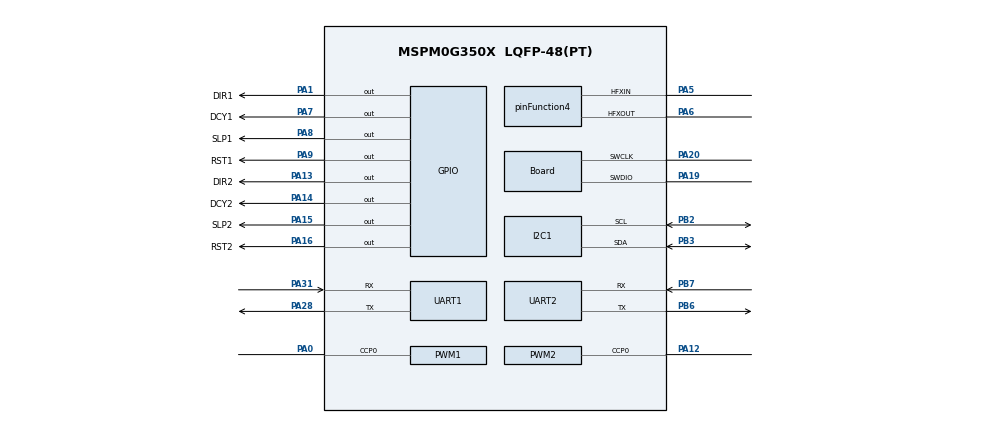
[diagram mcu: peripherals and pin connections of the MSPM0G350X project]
/**
 * @cliArgs --device "MSPM0G350X" --part "Default" --package "LQFP-48(PT)" --product "mspm0_sdk@2.05.01.00"
 * @versions {"tool":"1.24.1+4189"}
 */

/**
 * Import the modules used in this configuration.
 */
const GPIO   = scripting.addModule("/ti/driverlib/GPIO", {}, false);
const GPIO1  = GPIO.addInstance();
const GPIO2  = GPIO.addInstance();
const I2C    = scripting.addModule("/ti/driverlib/I2C", {}, false);
const I2C1   = I2C.addInstance();
const PWM    = scripting.addModule("/ti/driverlib/PWM", {}, false);
const PWM1   = PWM.addInstance();
const PWM2   = PWM.addInstance();
const SYSCTL = scripting.addModule("/ti/driverlib/SYSCTL");
const UART   = scripting.addModule("/ti/driverlib/UART", {}, false);
const UART1  = UART.addInstance();
const UART2  = UART.addInstance();

/**
 * Write custom configuration values to the imported modules.
 */
const divider9       = system.clockTree["UDIV"];
divider9.divideValue = 2;

const multiplier2         = system.clockTree["PLL_QDIV"];
multiplier2.multiplyValue = 5;

const mux4       = system.clockTree["EXHFMUX"];
mux4.inputSelect = "EXHFMUX_XTAL";

const mux8       = system.clockTree["HSCLKMUX"];
mux8.inputSelect = "HSCLKMUX_SYSPLL0";

const pinFunction4                        = system.clockTree["HFXT"];
pinFunction4.inputFreq                    = 40;
pinFunction4.enable                       = true;
pinFunction4.peripheral.$assign           = "SYSCTL";
pinFunction4.peripheral.hfxInPin.$assign  = "PA5";
pinFunction4.peripheral.hfxOutPin.$assign = "PA6";

GPIO1.$name                         = "STEP_MOTOR1";
GPIO1.port                          = "PORTA";
GPIO1.associatedPins.create(4);
GPIO1.associatedPins[0].$name       = "DIR1";
GPIO1.associatedPins[0].pin.$assign = "PA1";
GPIO1.associatedPins[1].$name       = "DCY1";
GPIO1.associatedPins[1].pin.$assign = "PA7";
GPIO1.associatedPins[2].$name       = "SLP1";
GPIO1.associatedPins[2].pin.$assign = "PA8";
GPIO1.associatedPins[3].$name       = "RST1";
GPIO1.associatedPins[3].pin.$assign = "PA9";

const Board                       = scripting.addModule("/ti/driverlib/Board", {}, false);
Board.peripheral.$assign          = "DEBUGSS";
Board.peripheral.swclkPin.$assign = "PA20";
Board.peripheral.swdioPin.$assign = "PA19";

GPIO2.$name                         = "STEP_MOTOR2";
GPIO2.port                          = "PORTA";
GPIO2.associatedPins.create(4);
GPIO2.associatedPins[0].$name       = "DIR2";
GPIO2.associatedPins[0].pin.$assign = "PA13";
GPIO2.associatedPins[1].$name       = "DCY2";
GPIO2.associatedPins[1].pin.$assign = "PA14";
GPIO2.associatedPins[2].$name       = "SLP2";
GPIO2.associatedPins[2].pin.$assign = "PA15";
GPIO2.associatedPins[3].$name       = "RST2";
GPIO2.associatedPins[3].pin.$assign = "PA16";

I2C1.$name                             = "OLED";
I2C1.basicEnableController             = true;
I2C1.advDigitalGlitchFilter            = "CLOCKS_1";
I2C1.advControllerRXFIFOTRIG           = "BYTES_8";
I2C1.advControllerTXFIFOTRIG           = "BYTES_7";
I2C1.enableDMAEvent1                   = false;
I2C1.enableDMAEvent2                   = false;
I2C1.peripheral.$assign                = "I2C1";
I2C1.peripheral.sdaPin.$assign         = "PB3";
I2C1.peripheral.sclPin.$assign         = "PB2";
I2C1.sdaPinConfig.$name                = "ti_driverlib_gpio_GPIOPinGeneric0";
I2C1.sdaPinConfig.hideOutputInversion  = scripting.forceWrite(false);
I2C1.sdaPinConfig.onlyInternalResistor = scripting.forceWrite(false);
I2C1.sdaPinConfig.passedPeripheralType = scripting.forceWrite("Digital");
I2C1.sdaPinConfig.enableConfig         = true;
I2C1.sdaPinConfig.internalResistor     = "PULL_UP";
I2C1.sclPinConfig.$name                = "ti_driverlib_gpio_GPIOPinGeneric1";
I2C1.sclPinConfig.hideOutputInversion  = scripting.forceWrite(false);
I2C1.sclPinConfig.onlyInternalResistor = scripting.forceWrite(false);
I2C1.sclPinConfig.passedPeripheralType = scripting.forceWrite("Digital");
I2C1.sclPinConfig.enableConfig         = true;
I2C1.sclPinConfig.internalResistor     = "PULL_UP";

PWM1.$name                              = "DCC_100_PWM1";
PWM1.ccIndex                            = [0];
PWM1.clockDivider                       = 8;
PWM1.timerCount                         = 10000;
PWM1.pwmMode                            = "EDGE_ALIGN_UP";
PWM1.interrupts                         = ["LOAD_EVENT"];
PWM1.PWM_CHANNEL_0.$name                = "ti_driverlib_pwm_PWMTimerCC1";
PWM1.PWM_CHANNEL_0.dutyCycle            = 50;
PWM1.ccp0PinConfig.direction            = scripting.forceWrite("OUTPUT");
PWM1.ccp0PinConfig.hideOutputInversion  = scripting.forceWrite(false);
PWM1.ccp0PinConfig.onlyInternalResistor = scripting.forceWrite(false);
PWM1.ccp0PinConfig.passedPeripheralType = scripting.forceWrite("Digital");
PWM1.ccp0PinConfig.$name                = "ti_driverlib_gpio_GPIOPinGeneric5";
PWM1.peripheral.$assign                 = "TIMA0";
PWM1.peripheral.ccp0Pin.$assign         = "PA0";

PWM2.$name                              = "DCC_100_PWM2";
PWM2.ccIndex                            = [0];
PWM2.clockDivider                       = 8;
PWM2.timerCount                         = 10000;
PWM2.pwmMode                            = "EDGE_ALIGN_UP";
PWM2.interrupts                         = ["LOAD_EVENT"];
PWM2.PWM_CHANNEL_0.$name                = "ti_driverlib_pwm_PWMTimerCC0";
PWM2.PWM_CHANNEL_0.dutyCycle            = 50;
PWM2.ccp0PinConfig.$name                = "ti_driverlib_gpio_GPIOPinGeneric4";
PWM2.ccp0PinConfig.direction            = scripting.forceWrite("OUTPUT");
PWM2.ccp0PinConfig.hideOutputInversion  = scripting.forceWrite(false);
PWM2.ccp0PinConfig.onlyInternalResistor = scripting.forceWrite(false);
PWM2.ccp0PinConfig.passedPeripheralType = scripting.forceWrite("Digital");
PWM2.peripheral.$assign                 = "TIMG0";
PWM2.peripheral.ccp0Pin.$assign         = "PA12";

SYSCTL.forceDefaultClkConfig = true;
SYSCTL.clockTreeEn           = true;

UART1.targetBaudRate                   = 115200;
UART1.enabledInterrupts                = ["RX"];
UART1.$name                            = "PRINT";
UART1.peripheral.$assign               = "UART0";
UART1.peripheral.rxPin.$assign         = "PA31";
UART1.peripheral.txPin.$assign         = "PA28";
UART1.txPinConfig.direction            = scripting.forceWrite("OUTPUT");
UART1.txPinConfig.hideOutputInversion  = scripting.forceWrite(false);
UART1.txPinConfig.onlyInternalResistor = scripting.forceWrite(false);
UART1.txPinConfig.passedPeripheralType = scripting.forceWrite("Digital");
UART1.txPinConfig.$name                = "ti_driverlib_gpio_GPIOPinGeneric2";
UART1.rxPinConfig.hideOutputInversion  = scripting.forceWrite(false);
UART1.rxPinConfig.onlyInternalResistor = scripting.forceWrite(false);
UART1.rxPinConfig.passedPeripheralType = scripting.forceWrite("Digital");
UART1.rxPinConfig.$name                = "ti_driverlib_gpio_GPIOPinGeneric3";

UART2.targetBaudRate                   = 115200;
UART2.enabledInterrupts                = ["RX"];
UART2.$name                            = "DEBUG";
UART2.peripheral.$assign               = "UART1";
UART2.peripheral.rxPin.$assign         = "PB7";
UART2.peripheral.txPin.$assign         = "PB6";
UART2.txPinConfig.direction            = scripting.forceWrite("OUTPUT");
UART2.txPinConfig.hideOutputInversion  = scripting.forceWrite(false);
UART2.txPinConfig.onlyInternalResistor = scripting.forceWrite(false);
UART2.txPinConfig.passedPeripheralType = scripting.forceWrite("Digital");
UART2.txPinConfig.$name                = "ti_driverlib_gpio_GPIOPinGeneric6";
UART2.rxPinConfig.hideOutputInversion  = scripting.forceWrite(false);
UART2.rxPinConfig.onlyInternalResistor = scripting.forceWrite(false);
UART2.rxPinConfig.passedPeripheralType = scripting.forceWrite("Digital");
UART2.rxPinConfig.$name                = "ti_driverlib_gpio_GPIOPinGeneric7";

const ProjectConfig              = scripting.addModule("/ti/project_config/ProjectConfig", {}, false);
ProjectConfig.migrationCondition = true;
